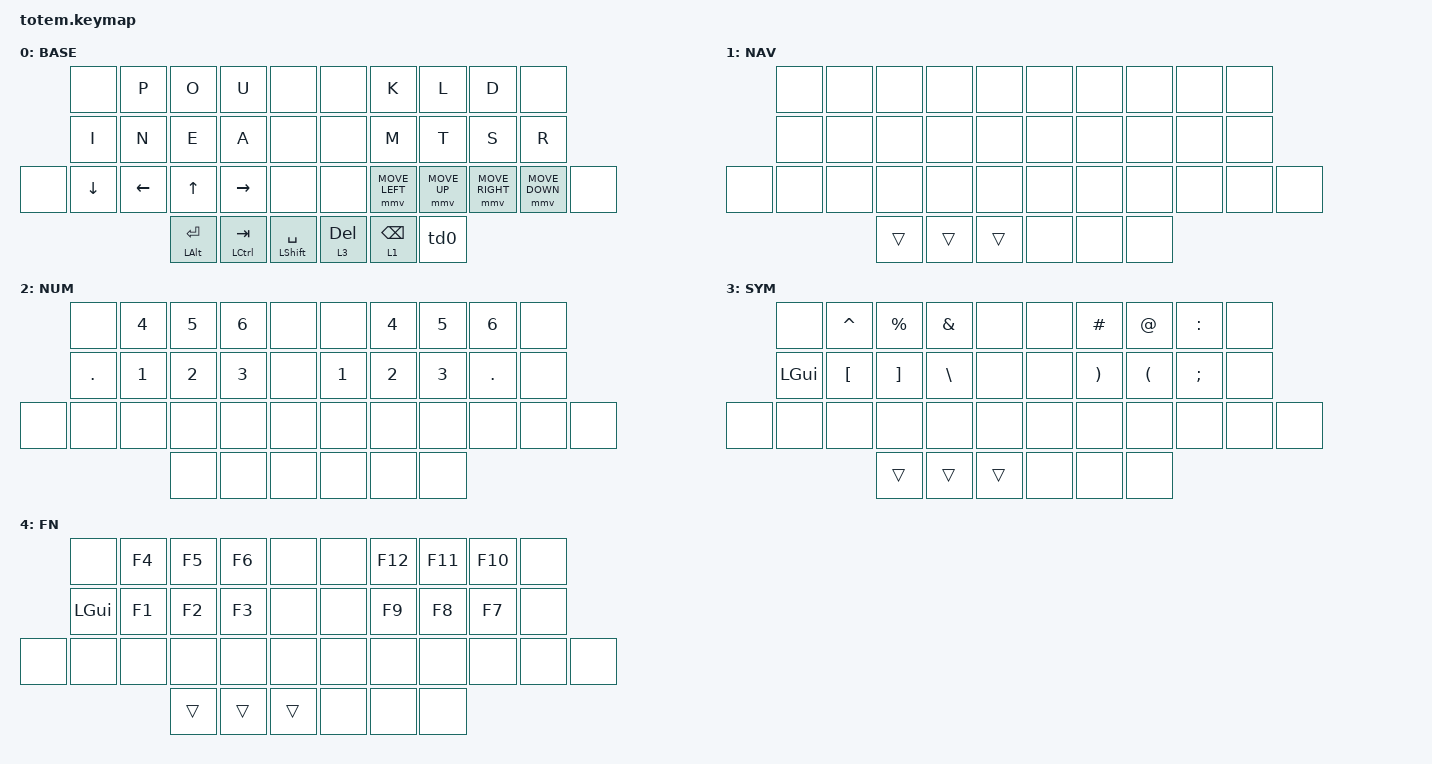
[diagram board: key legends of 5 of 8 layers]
/*
 * ZMK Keymap for Totem Split Keyboard (38 keys)
 * Customized with adjusted combo key positions & Layer 3 numpad combos.
 */

#include <behaviors.dtsi>
#include <dt-bindings/zmk/keys.h>
#include <dt-bindings/zmk/bt.h>
#include <dt-bindings/zmk/pointing.h>

/ {
    behaviors {
        /* Tap Dance 0: Single Tap = Left Click, Double Tap = Middle Click */
        td0: tap_dance_0 {
            compatible = "zmk,behavior-tap-dance";
            #binding-cells = <0>;
            tapping-term-ms = <170>;
            bindings = <&mkp LCLK>, <&mkp MCLK>;
        };
    };
 
    combos {
        compatible = "zmk,combos";
 
        /* ================================================================== */
        /*                       BASE LAYER (LAYER 0) COMBOS                  */
        /* ================================================================== */
        combo_minus    { timeout-ms = <50>; key-positions = <12 34>;   layers = <0>; bindings = <&kp MINUS>; };
        combo_j        { timeout-ms = <50>; key-positions = <3 34>;   layers = <0>; bindings = <&kp J>; };
        combo_g        { timeout-ms = <50>; key-positions = <13 34>;   layers = <0>; bindings = <&kp G>; };
        combo_b        { timeout-ms = <50>; key-positions = <16 35>; layers = <0>; bindings = <&kp B>; };
        combo_h        { timeout-ms = <50>; key-positions = <17 35>; layers = <0>; bindings = <&kp H>; };
        combo_c        { timeout-ms = <50>; key-positions = <6 35>; layers = <0>; bindings = <&kp C>; };
 
        combo_q        { timeout-ms = <50>; key-positions = <11 34>;   layers = <0>; bindings = <&kp Q>; };
        combo_w        { timeout-ms = <50>; key-positions = <8 35>;   layers = <0>; bindings = <&kp W>; };
        combo_v        { timeout-ms = <50>; key-positions = <7 35>; layers = <0>; bindings = <&kp V>; };
        combo_x        { timeout-ms = <50>; key-positions = <19 35>; layers = <0>; bindings = <&kp X>; };
 
        combo_z        { timeout-ms = <50>; key-positions = <1 34>;   layers = <0>; bindings = <&kp Z>; };
        combo_y        { timeout-ms = <50>; key-positions = <2 34>;   layers = <0>; bindings = <&kp Y>; };
        combo_f        { timeout-ms = <50>; key-positions = <18 35>; layers = <0>; bindings = <&kp F>; };
 
        combo_excl     { timeout-ms = <50>; key-positions = <3 10>;   layers = <0>; bindings = <&kp EXCL>; };
        combo_question { timeout-ms = <50>; key-positions = <2 10>;   layers = <0>; bindings = <&kp QUESTION>; };
        combo_slash    { timeout-ms = <50>; key-positions = <1 10>;   layers = <0>; bindings = <&kp SLASH>; };
        combo_comma    { timeout-ms = <50>; key-positions = <12 10>;   layers = <0>; bindings = <&kp COMMA>; };
        combo_dot      { timeout-ms = <50>; key-positions = <13 10>;   layers = <0>; bindings = <&kp DOT>; };
 
        combo_bspc     { timeout-ms = <50>; key-positions = <2 11>;   layers = <0>; bindings = <&kp BSPC>; };
        combo_del      { timeout-ms = <50>; key-positions = <2 13>;   layers = <0>; bindings = <&kp DEL>; };
 
        /* One-Shot Modifiers (Triggered via R [pos 28] + M / T / S / D) */
        combo_osm_shift { timeout-ms = <50>; key-positions = <16 17>; layers = <0>; bindings = <&sk LSHFT>; };
        combo_osm_alt   { timeout-ms = <50>; key-positions = <6 7>; layers = <0>; bindings = <&sk LALT>; };
        combo_osm_ctrl  { timeout-ms = <50>; key-positions = <17 18>; layers = <0>; bindings = <&sk LCTRL>; };
        combo_osm_gui   { timeout-ms = <50>; key-positions = <7 8>; layers = <0>; bindings = <&sk LGUI>; };
 
        /* ================================================================== */
        /*                 LAYER 3 (NUMPAD) COMBOS - LEFT HAND                */
        /* ================================================================== */
        combo_l3_n7_lh    { timeout-ms = <50>; key-positions = <11 12>; layers = <3>; bindings = <&kp N7>; };
        combo_l3_n8_lh    { timeout-ms = <50>; key-positions = <12 13>; layers = <3>; bindings = <&kp N8>; };
        combo_l3_n9_lh    { timeout-ms = <50>; key-positions = <1 2>; layers = <3>; bindings = <&kp N9>; };
        combo_l3_n0_lh    { timeout-ms = <50>; key-positions = <2 3>; layers = <3>; bindings = <&kp N0>; };
        combo_l3_minus_lh { timeout-ms = <50>; key-positions = <10 13>; layers = <3>; bindings = <&kp MINUS>; };
        combo_l3_plus_lh  { timeout-ms = <50>; key-positions = <10 12>; layers = <3>; bindings = <&kp PLUS>; };
        combo_l3_equal_lh { timeout-ms = <50>; key-positions = <10 11>; layers = <3>; bindings = <&kp EQUAL>; };
        combo_l3_slash_lh { timeout-ms = <50>; key-positions = <10 3>; layers = <3>; bindings = <&kp SLASH>; };
        combo_l3_astrk_lh { timeout-ms = <50>; key-positions = <10 2>; layers = <3>; bindings = <&kp ASTRK>; };
        combo_l3_bspc_lh  { timeout-ms = <50>; key-positions = <10 1>; layers = <3>; bindings = <&kp BSPC>; };
 
        /* ================================================================== */
        /*                LAYER 3 (NUMPAD) COMBOS - RIGHT HAND                */
        /* ================================================================== */
        combo_l3_n7_rh    { timeout-ms = <50>; key-positions = <16 17>; layers = <3>; bindings = <&kp N7>; };
        combo_l3_n8_rh    { timeout-ms = <50>; key-positions = <17 18>; layers = <3>; bindings = <&kp N8>; };
        combo_l3_n9_rh    { timeout-ms = <50>; key-positions = <6 7>; layers = <3>; bindings = <&kp N9>; };
        combo_l3_n0_rh    { timeout-ms = <50>; key-positions = <7 8>; layers = <3>; bindings = <&kp N0>; };
        combo_l3_minus_rh { timeout-ms = <50>; key-positions = <16 19>; layers = <3>; bindings = <&kp MINUS>; };
        combo_l3_plus_rh  { timeout-ms = <50>; key-positions = <17 19>; layers = <3>; bindings = <&kp PLUS>; };
        combo_l3_equal_rh { timeout-ms = <50>; key-positions = <18 19>; layers = <3>; bindings = <&kp EQUAL>; };
        combo_l3_slash_rh { timeout-ms = <50>; key-positions = <6 19>; layers = <3>; bindings = <&kp SLASH>; };
        combo_l3_astrk_rh { timeout-ms = <50>; key-positions = <7 19>; layers = <3>; bindings = <&kp ASTRK>; };
        combo_l3_bspc_rh  { timeout-ms = <50>; key-positions = <8 19>; layers = <3>; bindings = <&kp BSPC>; };
    };
 
    /* ================================================================== */
    /*                              KEYMAP                                */
    /* ================================================================== */
    keymap {
        compatible = "zmk,keymap";
 
        base_layer {
            label = "BASE";
            bindings = <
                 &none           &kp P            &kp O           &kp U           &none            &none        &kp K           &kp L           &kp D           &none
                 &kp I           &kp N            &kp E           &kp A           &none            &none        &kp M           &kp T           &kp S           &kp R
    &none        &kp DOWN        &kp LEFT         &kp UP          &kp RIGHT       &none            &none        &mmv MOVE_LEFT  &mmv MOVE_UP    &mmv MOVE_RIGHT &mmv MOVE_DOWN  &none
                                                  &mt LALT ENTER  &mt LCTRL TAB   &mt LSHFT SPACE  &lt 3 DEL       &lt 1 BSPC   &td0            
            >;
        };
 
        nav_media_layer {
            label = "NAV";
            bindings = <
                 &none        &none           &none           &none           &none            &none        &none           &none           &none       &none
                 &none        &none           &none           &none           &none            &none        &none           &none           &none       &none
    &none        &none        &none           &none           &none           &none            &none        &none           &none           &none       &none        &none        
                                              &trans          &trans          &trans           &none        &none           &none     
            >;
        };
 
        num_layer {
            label = "NUM";
            bindings = <
                 &none        &kp N4           &kp N5          &kp N6          &none            &none        &kp N4          &kp N5          &kp N6          &none
                 &kp DOT      &kp N1           &kp N2          &kp N3          &none            &kp N1       &kp N2          &kp N3          &kp DOT         &none
    &none        &none        &none            &none           &none           &none            &none        &none           &none           &none           &none     &none        
                                               &none           &none            &none        &none           &none           &none
            >;
        };
 
        sym_layer {
            label = "SYM";
            bindings = <
                 &none        &kp CARET        &kp PRCNT       &kp AMPS        &none            &none        &kp HASH        &kp AT          &kp COLON       &none
                 &kp LGUI     &kp LBKT         &kp RBKT        &kp BSLH        &none            &none        &kp RPAR        &kp LPAR        &kp SEMI        &none
    &none        &none        &none            &none           &none           &none            &none        &none           &none           &none           &none    &none        
                                              &trans          &trans          &trans           &none        &none           &none     
            >;
        };
 
        fn_layer {
            label = "FN";
            bindings = <
                 &none        &kp F4       &kp F5          &kp F6          &none            &none        &kp F12      &kp F11         &kp F10         &none
                 &kp LGUI     &kp F1       &kp F2          &kp F3          &none            &none        &kp F9       &kp F8          &kp F7          &none
    &none        &none        &none        &none           &none           &none           &none         &none        &none           &none           &none           &none
                                           &trans          &trans          &trans           &none        &none        &none     
            >;
        };
 
        misc1_layer {
            label = "MISC1";
            bindings = <
                 &none        &none            &none           &none           &none            &none        &none           &none           &none           &none
                 &none        &none            &none           &none           &none            &none        &none           &none           &none           &none
    &none        &none        &none            &none           &none           &none            &none        &none           &none           &none           &none     &none        
                                               &trans          &trans          &trans           &none        &none           &none           &none
            >;
        };
 
        misc2_layer {
            label = "MISC2";
            bindings = <
                 &none        &none            &none           &none           &none            &none        &none           &none           &none           &none
                 &none        &none            &none           &none           &none            &none        &none           &none           &none           &none
    &none        &none        &none            &none           &none           &none            &none        &none           &none           &none           &none     &none        
                                               &trans          &trans          &trans           &none        &none           &none           &none
            >;
        };
 
        misc3_layer {
            label = "MISC3";
            bindings = <
                 &none        &none            &none           &none           &none            &none        &none           &none           &none           &none
                 &none        &none            &none           &none           &none            &none        &none           &none           &none           &none
    &none        &none        &none            &none           &none           &none            &none        &none           &none           &none           &none     &none        
                                               &trans          &trans          &trans           &none        &none           &none           &none
            >;
        };
    };
};
